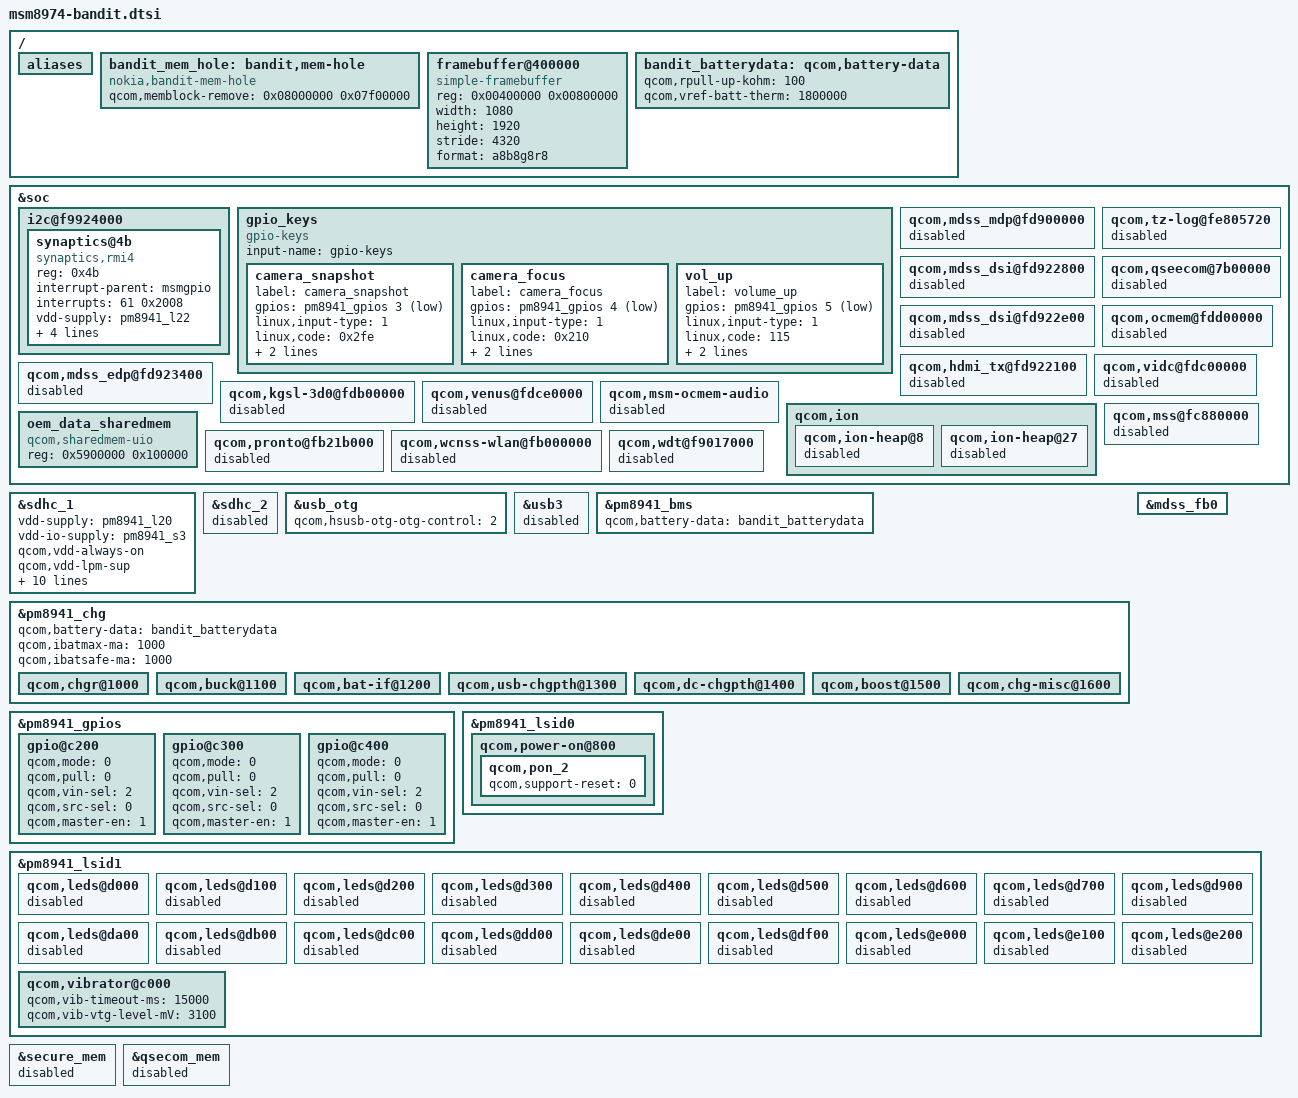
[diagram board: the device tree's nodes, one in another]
/*
 * Nokia Lumia 1520 (bandit), board description for the Android 3.4 kernel.
 *
 * Copyright (c) 2013, The Linux Foundation. All rights reserved.
 * Copyright (c) 2026, Lorenzo Giannoccaro.
 *
 * This program is free software; you can redistribute it and/or modify
 * it under the terms of the GNU General Public License version 2 and
 * only version 2 as published by the Free Software Foundation.
 *
 * Hardware facts (touch wiring, buttons, framebuffer, regulators) come from
 * the mainline bring-up by KorelisLabs (lumia-1520-mainline) and the stock
 * ACPI tables; the PMIC/USB/eMMC setup follows the Qualcomm MTP, which the
 * 1520 board closely matches.
 *
 * The phone boots through the Windows Phone firmware: Nokia UEFI ->
 * bootmgr -> BootShim -> lk1st. Its TrustZone does not implement several
 * SCM calls used by Android kernels; see arch/arm/mach-msm/tz-restricted.c.
 */

/ {
	aliases {
		/* No user-accessible UART on the 1520 */
	};

	/*
	 * The kernel runs with PHYS_OFFSET 0x10000000 (lk1st loads it at
	 * 0x10008000), so RAM below 256 MB is not used: it holds the UEFI
	 * framebuffer (0x00400000), the CPU parking mailboxes (0x00300000)
	 * and the firmware carve-outs. The carve-outs are listed here as well
	 * (modem, mba, wcnss, adsp, venus, smem, tz, rfsa, rmtfs; same map as
	 * mainline qcom-msm8974.dtsi, verified on the 1520 by the mainline
	 * port) so they stay out of the memory map if PHYS_OFFSET changes.
	 */
	bandit_mem_hole: bandit,mem-hole {
		compatible = "nokia,bandit-mem-hole";
		qcom,memblock-remove = <0x08000000 0x07f00000>;
	};

	/*
	 * Boot console on the panel and buffer left running by the UEFI
	 * (1080x1920, 32 bpp, address read from the MDP RGB0 pipe by the
	 * mainline port). The display hardware is not touched.
	 */
	framebuffer@400000 {
		compatible = "simple-framebuffer";
		reg = <0x00400000 0x00800000>;
		width = <1080>;
		height = <1920>;
		stride = <4320>;
		format = "a8b8g8r8";	/* RGB0 set to R,G,B,A by bandit-splash.c */
	};
};

&soc {
	/* Touchscreen: Synaptics PLG0175-02 (RMI4), from the stock DSDT */
	i2c@f9924000 {
		synaptics@4b {
			compatible = "synaptics,rmi4";
			reg = <0x4b>;
			interrupt-parent = <&msmgpio>;
			interrupts = <61 0x2008>;
			vdd-supply = <&pm8941_l22>;
			vcc_i2c-supply = <&pm8941_l6>;
			synaptics,reset-gpio = <&msmgpio 60 0x00>;
			synaptics,irq-gpio = <&msmgpio 61 0x2008>;
			/*
			 * No display-coords: this driver reports raw sensor
			 * coordinates, so the axes must use the sensor range
			 * read from F11/F12 (Android scales it to the panel).
			 */
			synaptics,i2c-pull-up;
		};
	};

	gpio_keys {
		compatible = "gpio-keys";
		input-name = "gpio-keys";

		camera_snapshot {
			label = "camera_snapshot";
			gpios = <&pm8941_gpios 3 0x1>;
			linux,input-type = <1>;
			linux,code = <0x2fe>;
			gpio-key,wakeup;
			debounce-interval = <15>;
		};

		camera_focus {
			label = "camera_focus";
			gpios = <&pm8941_gpios 4 0x1>;
			linux,input-type = <1>;
			linux,code = <0x210>;
			gpio-key,wakeup;
			debounce-interval = <15>;
		};

		vol_up {
			label = "volume_up";
			gpios = <&pm8941_gpios 5 0x1>;
			linux,input-type = <1>;
			linux,code = <115>;
			gpio-key,wakeup;
			debounce-interval = <15>;
		};
	};

	/* Display: no panel driver yet, the boot console uses simple-framebuffer */
	qcom,mdss_mdp@fd900000 {
		status = "disabled";
	};
	qcom,mdss_dsi@fd922800 {
		status = "disabled";
	};
	qcom,mdss_dsi@fd922e00 {
		status = "disabled";
	};
	qcom,hdmi_tx@fd922100 {
		status = "disabled";
	};
	qcom,mdss_edp@fd923400 {
		status = "disabled";
	};

	/*
	 * First bring-up: keep off everything that needs TrustZone services
	 * the Windows Phone firmware may not provide (watchdog register save,
	 * TZ log, QSEECOM, secure IOMMU/OCMEM for GPU and video).
	 * They come back one at a time once the phone reaches a shell.
	 */
	qcom,tz-log@fe805720 {
		status = "disabled";
	};
	qcom,qseecom@7b00000 {
		status = "disabled";
	};
	qcom,ocmem@fdd00000 {
		status = "disabled";
	};
	qcom,kgsl-3d0@fdb00000 {
		status = "disabled";
	};
	qcom,vidc@fdc00000 {
		status = "disabled";
	};
	qcom,venus@fdce0000 {
		status = "disabled";
	};
};

&sdhc_1 {
	vdd-supply = <&pm8941_l20>;
	vdd-io-supply = <&pm8941_s3>;

	qcom,vdd-always-on;
	qcom,vdd-lpm-sup;
	qcom,vdd-voltage-level = <2950000 2950000>;
	qcom,vdd-current-level = <800 500000>;

	qcom,vdd-io-always-on;
	qcom,vdd-io-voltage-level = <1800000 1800000>;
	qcom,vdd-io-current-level = <250 154000>;

	qcom,pad-pull-on = <0x0 0x3 0x3>;
	qcom,pad-pull-off = <0x0 0x3 0x3>;
	qcom,pad-drv-on = <0x7 0x4 0x4>;
	qcom,pad-drv-off = <0x0 0x0 0x0>;

	qcom,nonremovable;
	status = "ok";
};

/* microSD: card-detect line not identified yet */
&sdhc_2 {
	status = "disabled";
};

/*
 * The micro-USB port is wired to the USB 2.0 controller at f9a55000 (the
 * mainline port drives it as ci_hdrc), not to the USB 3.0 core used by the
 * MTP. VBUS detection through the PM8941 charger.
 */
&usb_otg {
	status = "ok";
	qcom,hsusb-otg-otg-control = <2>;
};

&usb3 {
	status = "disabled";
};

/ {
	bandit_batterydata: qcom,battery-data {
		qcom,rpull-up-kohm = <100>;
		qcom,vref-batt-therm = <1800000>;

		/include/ "../batterydata-palladium.dtsi"
	};
};

&pm8941_bms {
	status = "ok";
	qcom,battery-data = <&bandit_batterydata>;
};

/*
 * Charging for the BV-4BW (3400 mAh, Li-ion, 4.35 V maximum): the PM8941
 * defaults stop at 4.20 V (vddsafe 4.23 V), reduce the current below 10 C
 * and above 45 C (battery thermistor through the BMS) and stop after
 * 150 minutes. Fast charge limited to 1 A for margin.
 */
&pm8941_chg {
	status = "ok";
	qcom,battery-data = <&bandit_batterydata>;
	qcom,ibatmax-ma = <1000>;
	qcom,ibatsafe-ma = <1000>;

	qcom,chgr@1000 {
		status = "ok";
	};
	qcom,buck@1100 {
		status = "ok";
	};
	qcom,bat-if@1200 {
		status = "ok";
	};
	qcom,usb-chgpth@1300 {
		status = "ok";
	};
	qcom,dc-chgpth@1400 {
		status = "ok";
	};
	qcom,boost@1500 {
		status = "ok";
	};
	qcom,chg-misc@1600 {
		status = "ok";
	};
};

&pm8941_gpios {
	gpio@c200 { /* GPIO 3: camera snapshot */
		qcom,mode = <0>;
		qcom,pull = <0>;
		qcom,vin-sel = <2>;
		qcom,src-sel = <0>;
		qcom,master-en = <1>;
	};

	gpio@c300 { /* GPIO 4: camera focus */
		qcom,mode = <0>;
		qcom,pull = <0>;
		qcom,vin-sel = <2>;
		qcom,src-sel = <0>;
		qcom,master-en = <1>;
	};

	gpio@c400 { /* GPIO 5: volume up */
		qcom,mode = <0>;
		qcom,pull = <0>;
		qcom,vin-sel = <2>;
		qcom,src-sel = <0>;
		qcom,master-en = <1>;
	};
};

/* Volume down (RESIN): key only, no PMIC reset on a long press */
&pm8941_lsid0 {
	qcom,power-on@800 {
		qcom,pon_2 {
			qcom,support-reset = <0>;
		};
	};
};

/*
 * The MTP/OnePlus splash carve-out (0x03200000) lies below PHYS_OFFSET on
 * the 1520 (the kernel runs from 0x10000000) and is not the UEFI
 * framebuffer (0x00400000): reserving it made bootmem BUG() in paging_init.
 */
&mdss_fb0 {
	/delete-property/ qcom,memblock-reserve;
};

/*
 * LEDs: msm-pm8941.dtsi declares the qcom,leds-qpnp peripherals without
 * child nodes, so every probe fails with -ECHILD. The 1520 has no RGB or
 * PM8941 flash (its flash is an external part on TLMM GPIO 83/84, stock
 * DSDT QCOM0705) and the keypad backlight is not identified yet: switch
 * them off. The WLED (leds@d800) drives the LCD backlight; it is left as
 * the UEFI set it until its configuration is tested on the phone.
 */
&pm8941_lsid1 {
	qcom,leds@d000 {
		status = "disabled";
	};
	qcom,leds@d100 {
		status = "disabled";
	};
	qcom,leds@d200 {
		status = "disabled";
	};
	qcom,leds@d300 {
		status = "disabled";
	};
	qcom,leds@d400 {
		status = "disabled";
	};
	qcom,leds@d500 {
		status = "disabled";
	};
	qcom,leds@d600 {
		status = "disabled";
	};
	qcom,leds@d700 {
		status = "disabled";
	};
	qcom,leds@d900 {
		status = "disabled";
	};
	qcom,leds@da00 {
		status = "disabled";
	};
	qcom,leds@db00 {
		status = "disabled";
	};
	qcom,leds@dc00 {
		status = "disabled";
	};
	qcom,leds@dd00 {
		status = "disabled";
	};
	qcom,leds@de00 {
		status = "disabled";
	};
	qcom,leds@df00 {
		status = "disabled";
	};
	qcom,leds@e000 {
		status = "disabled";
	};
	qcom,leds@e100 {
		status = "disabled";
	};
	qcom,leds@e200 {
		status = "disabled";
	};
};

/* OCMEM is disabled above: its audio client would defer forever */
&soc {
	qcom,msm-ocmem-audio {
		status = "disabled";
	};
};

/*
 * Content protection: the Windows Phone TrustZone runs no Android QSEE
 * apps, so the secure (CP_MM) and QSEECOM heaps cannot be used and nothing
 * enabled allocates from them. Dropping their CMA regions returns about
 * 272 MB to normal allocations; ION keeps the system, adsp, audio and PIL
 * heaps.
 */
&secure_mem {
	status = "disabled";
};

&qsecom_mem {
	status = "disabled";
};

&soc {
	qcom,ion {
		qcom,ion-heap@8 {
			status = "disabled";
		};
		qcom,ion-heap@27 {
			status = "disabled";
		};
	};
};

/*
 * rmt_storage (Qualcomm blob from the msm8974 common vendor) refuses to
 * start without an "oem_data" shared memory UIO, an Oppo addition. Give it
 * the same 1 MB window as the Oppo device tree: 0x05900000 is below
 * PHYS_OFFSET on the 1520, so the kernel does not use it, and it stays
 * clear of the PIL region at 0x05d00000.
 */
&soc {
	oem_data_sharedmem {
		compatible = "qcom,sharedmem-uio";
		reg = <0x5900000 0x100000>;
		reg-names = "oem_data";
	};
};

/*
 * Modem and WCNSS (Pronto) are off until their bring-up is solved: the PBL
 * rejects the Windows MBA ("PBL returned unexpected status"), and Pronto
 * never signals ready after PAS (mainline port finding). With the nodes on,
 * every QMI/SMD client retried subsystem_get("modem") every 1-2 s
 * (mss_start, MBA load, failure) and the Wi-Fi HAL kept starting WCNSS;
 * the mainline port saw failed Pronto startups end in full device resets,
 * a likely cause of the spontaneous reboots after 10-15 minutes. Without
 * the nodes the requests fail at once.
 */
&soc {
	qcom,mss@fc880000 {
		status = "disabled";
	};
	qcom,pronto@fb21b000 {
		status = "disabled";
	};
	qcom,wcnss-wlan@fb000000 {
		status = "disabled";
	};
};

/*
 * Vibration motor on the PM8941 (stock DSDT VIB1 "NOKIA_VIBRA_PMIC", SPMI
 * SID 1 at 0xC0xx): timed_output/vibrator. Level and timeout as on the
 * Qualcomm reference boards.
 */
&pm8941_lsid1 {
	qcom,vibrator@c000 {
		status = "okay";
		qcom,vib-timeout-ms = <15000>;
		qcom,vib-vtg-level-mV = <3100>;
	};
};

/*
 * APSS watchdog: kept off. Enabling the driver (560ac391) froze the boot at
 * the watchdog probe and the SoC reset about 10 s later, in a loop: the
 * Windows Phone firmware does not let Linux program it this way. Why the
 * system still resets about 10 minutes after boot is open.
 */
&soc {
	qcom,wdt@f9017000 {
		status = "disabled";
	};
};
